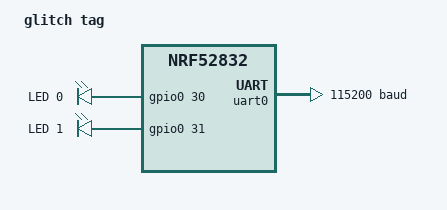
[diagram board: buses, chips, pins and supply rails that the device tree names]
/*
 * SPDX-License-Identifier: Apache-2.0
 */

/dts-v1/;
#include <nordic/nrf52832_qfaa.dtsi>
#include "glitch_tag-pinctrl.dtsi"
#include <zephyr/dt-bindings/input/input-event-codes.h>

/ {
	model = "glitch tag";

	chosen {
		zephyr,console = &uart0;
		zephyr,shell-uart = &uart0;
		zephyr,bt-mon-uart = &uart0;
		zephyr,bt-c2h-uart = &uart0;
		zephyr,sram = &sram0;
		zephyr,flash = &flash0;
	};

	leds {
		compatible = "gpio-leds";
		led0: led_0 {
			gpios = <&gpio0 30 GPIO_ACTIVE_HIGH>;
			label = "LED 0";
		};
		led1: led_1 {
			gpios = <&gpio0 31 GPIO_ACTIVE_HIGH>;
			label = "LED 1";
		};
	};

	/* These aliases are provided for compatibility with samples */
	aliases {
		led0 = &led0;
		led1 = &led1;
	};
};

&uicr {
	gpio-as-nreset;
};

&gpiote {
	status = "okay";
};

&gpio0 {
	status = "okay";
};

&uart0 {
	status = "okay";
	compatible = "nordic,nrf-uarte";
	current-speed = <115200>;
	pinctrl-0 = <&uart0_default>;
	pinctrl-names = "default";
};

